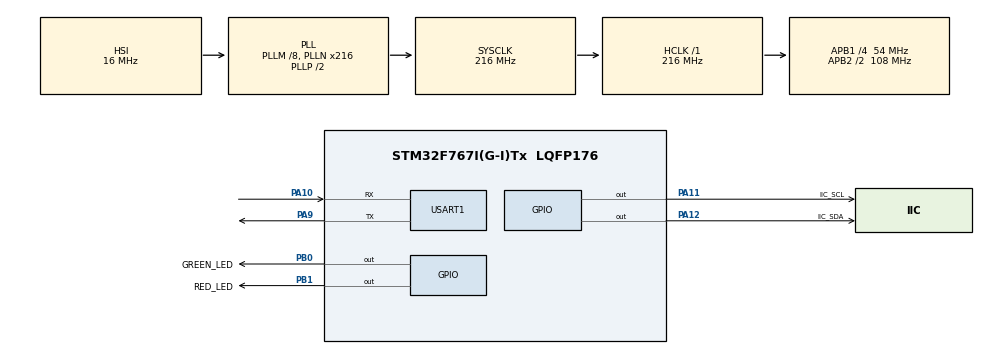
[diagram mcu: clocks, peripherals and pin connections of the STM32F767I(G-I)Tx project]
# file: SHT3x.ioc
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Mcu.Family=STM32F7
Mcu.Name=STM32F767I(G-I)Tx
Mcu.Package=LQFP176
NVIC.PriorityGroup=NVIC_PRIORITYGROUP_4
NVIC.TIM6_DAC_IRQn=true\:0\:0\:false\:false\:true\:false\:true\:true
NVIC.TimeBase=TIM6_DAC_IRQn
NVIC.TimeBaseIP=TIM6
PA10.Mode=Asynchronous
PA10.Signal=USART1_RX
PA11.GPIO_Label=IIC_SCL
PA11.GPIO_PuPd=GPIO_PULLUP
PA11.GPIO_Speed=GPIO_SPEED_FREQ_HIGH
PA11.PinState=GPIO_PIN_SET
PA11.Signal=GPIO_Output
PA12.GPIO_Label=IIC_SDA
PA12.GPIO_PuPd=GPIO_PULLUP
PA12.GPIO_Speed=GPIO_SPEED_FREQ_HIGH
PA12.PinState=GPIO_PIN_SET
PA12.Signal=GPIO_Output
PA13.Mode=Serial_Wire
PA13.Signal=SYS_JTMS-SWDIO
PA14.Mode=Serial_Wire
PA14.Signal=SYS_JTCK-SWCLK
PA9.Mode=Asynchronous
PA9.Signal=USART1_TX
PB0.GPIO_Label=GREEN_LED
PB0.GPIO_PuPd=GPIO_PULLUP
PB0.GPIO_Speed=GPIO_SPEED_FREQ_LOW
PB0.Signal=GPIO_Output
PB1.GPIO_Label=RED_LED
PB1.GPIO_PuPd=GPIO_PULLUP
PB1.Signal=GPIO_Output
PH0/OSC_IN.Mode=HSE-External-Oscillator
PH0/OSC_IN.Signal=RCC_OSC_IN
PH1/OSC_OUT.Mode=HSE-External-Oscillator
PH1/OSC_OUT.Signal=RCC_OSC_OUT
ProjectManager.HeapSize=0x200
ProjectManager.StackSize=0x400
ProjectManager.TargetToolchain=Makefile
RCC.AHBFreq_Value=216000000
RCC.APB1CLKDivider=RCC_HCLK_DIV4
RCC.APB1Freq_Value=54000000
RCC.APB1TimFreq_Value=108000000
RCC.APB2CLKDivider=RCC_HCLK_DIV2
RCC.APB2Freq_Value=108000000
RCC.APB2TimFreq_Value=216000000
RCC.CortexFreq_Value=216000000
RCC.HCLKFreq_Value=216000000
RCC.HSE_VALUE=25000000
RCC.HSI_VALUE=16000000
RCC.LSE_VALUE=32768
RCC.PLLM=8
RCC.PLLN=216
RCC.SYSCLKFreq_VALUE=216000000
RCC.SYSCLKSource=RCC_SYSCLKSOURCE_PLLCLK
RCC.USBFreq_Value=216000000
RCC.VCOOutputFreq_Value=432000000
USART1.VirtualMode-Asynchronous=VM_ASYNC
VP_SYS_VS_tim6.Mode=TIM6
board=custom

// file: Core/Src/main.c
/* USER CODE BEGIN Header */
/**
 ******************************************************************************
 * @file           : main.c
 * @brief          : Main program body
 ******************************************************************************
 * @attention
 *
 * <h2><center>&copy; Copyright (c) 2022 STMicroelectronics.
 * All rights reserved.</center></h2>
 *
 * This software component is licensed by ST under BSD 3-Clause license,
 * the "License"; You may not use this file except in compliance with the
 * License. You may obtain a copy of the License at:
 *                        opensource.org/licenses/BSD-3-Clause
 *
 ******************************************************************************
 */
/* USER CODE END Header */
#include "main.h"
#include "usart.h"
#include "gpio.h"

/* USER CODE BEGIN Includes */
#include <stdio.h>
#include "sht3x.h"
#include "hmc5983.h"
#include "iic_simulation.h"
#include "iic_hardware.h"
/* USER CODE END Includes */

void SystemClock_Config(void);

/* USER CODE BEGIN 0 */
iic_sim_interface_t iic_sim = {0};
sht3x_t sht3x = {0};
sht3x_status_t status;
hmc5983_t hmc5983 = {0};

/* USER CODE END 0 */

int main(void)
{
  /* USER CODE BEGIN 1 */
  sht3x_ret_t ret;
  /* USER CODE END 1 */

  /* MCU Configuration--------------------------------------------------------*/

  /* Reset of all peripherals, Initializes the Flash interface and the Systick. */
  HAL_Init();

  /* Configure the system clock */
  SystemClock_Config();

  /* Initialize all configured peripherals */
  MX_GPIO_Init();
  MX_USART1_UART_Init();
  /* USER CODE BEGIN 2 */
  iic_sim_init(&iic_sim, iic_hardware_get_drv());
  sht3x_init(&sht3x, &iic_sim);
  status = sht3x_read_status(&sht3x);
  // hmc5983_init(&hmc5983, &iic_sim, HMC_CONTINUOUS_MEASUREMENT);

  /* USER CODE END 2 */

  /* Infinite loop */
  while (1)
  {
    HAL_GPIO_TogglePin(RED_LED_GPIO_Port, RED_LED_Pin);
    HAL_Delay(1000);
    HAL_GPIO_TogglePin(GREEN_LED_GPIO_Port, GREEN_LED_Pin);
    ret = sht3x_read_humudity_tempture(&sht3x);
    printf("湿度:%.1f%%  温度:%.1f %x\r\n", ret.humidity, ret.tempture, *((uint16_t *)&status));
  }
}

void SystemClock_Config(void)
{
  RCC_OscInitTypeDef RCC_OscInitStruct = {0};
  RCC_ClkInitTypeDef RCC_ClkInitStruct = {0};

  /** Configure the main internal regulator output voltage
  */
  __HAL_RCC_PWR_CLK_ENABLE();
  __HAL_PWR_VOLTAGESCALING_CONFIG(PWR_REGULATOR_VOLTAGE_SCALE1);

  /** Initializes the RCC Oscillators according to the specified parameters
  * in the RCC_OscInitTypeDef structure.
  */
  RCC_OscInitStruct.OscillatorType = RCC_OSCILLATORTYPE_HSI;
  RCC_OscInitStruct.HSIState = RCC_HSI_ON;
  RCC_OscInitStruct.HSICalibrationValue = RCC_HSICALIBRATION_DEFAULT;
  RCC_OscInitStruct.PLL.PLLState = RCC_PLL_ON;
  RCC_OscInitStruct.PLL.PLLSource = RCC_PLLSOURCE_HSI;
  RCC_OscInitStruct.PLL.PLLM = 8;
  RCC_OscInitStruct.PLL.PLLN = 216;
  RCC_OscInitStruct.PLL.PLLP = RCC_PLLP_DIV2;
  RCC_OscInitStruct.PLL.PLLQ = 2;
  RCC_OscInitStruct.PLL.PLLR = 2;
  if (HAL_RCC_OscConfig(&RCC_OscInitStruct) != HAL_OK)
  {
    Error_Handler();
  }

  /** Activate the Over-Drive mode
  */
  if (HAL_PWREx_EnableOverDrive() != HAL_OK)
  {
    Error_Handler();
  }

  /** Initializes the CPU, AHB and APB buses clocks
  */
  RCC_ClkInitStruct.ClockType = RCC_CLOCKTYPE_HCLK|RCC_CLOCKTYPE_SYSCLK
                              |RCC_CLOCKTYPE_PCLK1|RCC_CLOCKTYPE_PCLK2;
  RCC_ClkInitStruct.SYSCLKSource = RCC_SYSCLKSOURCE_PLLCLK;
  RCC_ClkInitStruct.AHBCLKDivider = RCC_SYSCLK_DIV1;
  RCC_ClkInitStruct.APB1CLKDivider = RCC_HCLK_DIV4;
  RCC_ClkInitStruct.APB2CLKDivider = RCC_HCLK_DIV2;

  if (HAL_RCC_ClockConfig(&RCC_ClkInitStruct, FLASH_LATENCY_7) != HAL_OK)
  {
    Error_Handler();
  }
}

void HAL_TIM_PeriodElapsedCallback(TIM_HandleTypeDef *htim)
{
  if (htim->Instance == TIM6) {
    HAL_IncTick();
  }
}

void Error_Handler(void)
{
  __disable_irq();
  while (1)
  {
  }
}
